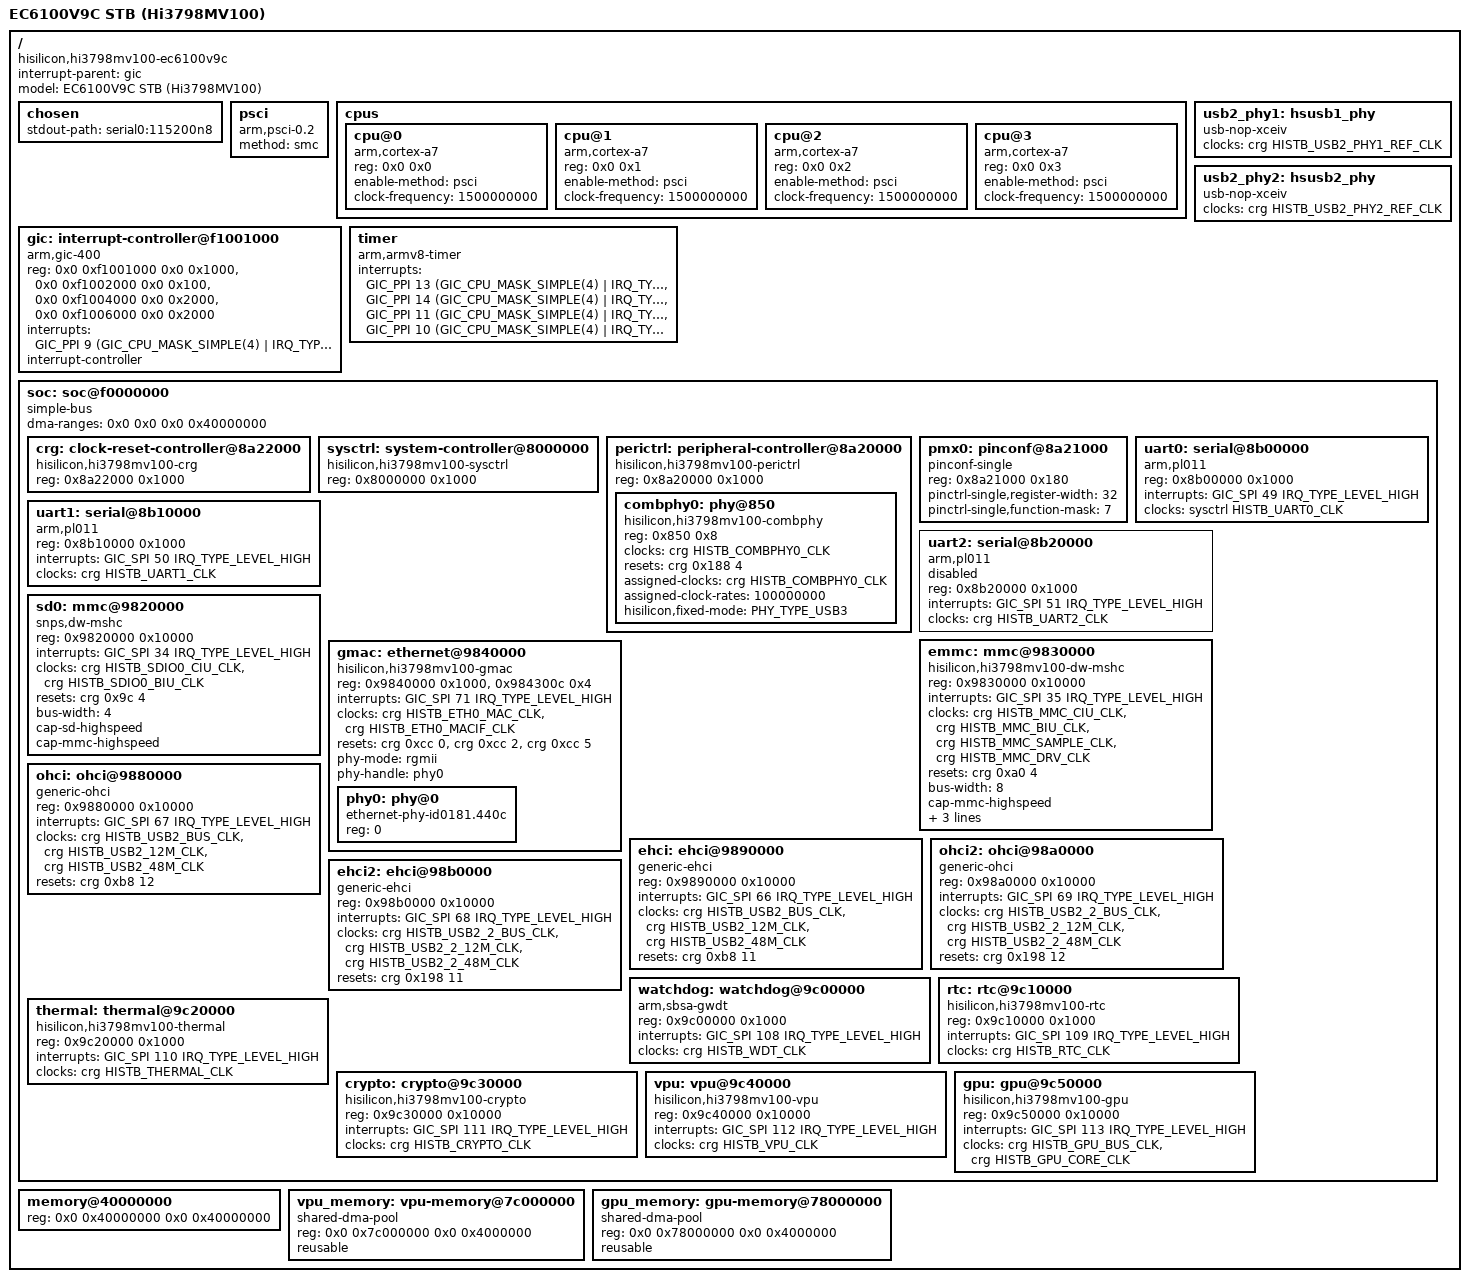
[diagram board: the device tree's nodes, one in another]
/*
 * Device Tree for EC6100V9C STB with Hi3798MV100 SoC
 * Based on Hi3798MV200 device tree and EC6108V9 OpenWrt port
 * Requires Hi3798MV100 kernel patches (David Yang v7, 2023)
 * 
 * SoC: HiSilicon Hi3798MV100
 * CPU: 4x Cortex-A7 @ 1.5GHz
 * RAM: 1GB DDR3
 * Flash: 8GB eMMC
 * Ethernet: 1x 100Mbps (internal GMAC)
 * USB: 2x USB 2.0
 * Video: 4K@30fps H.265/H.264 hardware decoding
 */

// SPDX-License-Identifier: GPL-2.0
/dts-v1/;

#include <dt-bindings/clock/histb-clock.h>
#include <dt-bindings/gpio/gpio.h>
#include <dt-bindings/interrupt-controller/arm-gic.h>
#include <dt-bindings/phy/phy.h>
#include <dt-bindings/reset/ti-syscon.h>

/ {
	compatible = "hisilicon,hi3798mv100-ec6100v9c", "hisilicon,hi3798mv100";
	interrupt-parent = <&gic>;
	#address-cells = <2>;
	#size-cells = <2>;

	model = "EC6100V9C STB (Hi3798MV100)";
	chosen {
		stdout-path = "serial0:115200n8";
	};

	psci {
		compatible = "arm,psci-0.2";
		method = "smc";
	};

	cpus {
		#address-cells = <2>;
		#size-cells = <0>;

		cpu@0 {
			compatible = "arm,cortex-a7";
			device_type = "cpu";
			reg = <0x0 0x0>;
			enable-method = "psci";
			clock-frequency = <1500000000>;
		};

		cpu@1 {
			compatible = "arm,cortex-a7";
			device_type = "cpu";
			reg = <0x0 0x1>;
			enable-method = "psci";
			clock-frequency = <1500000000>;
		};

		cpu@2 {
			compatible = "arm,cortex-a7";
			device_type = "cpu";
			reg = <0x0 0x2>;
			enable-method = "psci";
			clock-frequency = <1500000000>;
		};

		cpu@3 {
			compatible = "arm,cortex-a7";
			device_type = "cpu";
			reg = <0x0 0x3>;
			enable-method = "psci";
			clock-frequency = <1500000000>;
		};
	};

	gic: interrupt-controller@f1001000 {
		compatible = "arm,gic-400";
		reg = <0x0 0xf1001000 0x0 0x1000>,  /* GICD */
		      <0x0 0xf1002000 0x0 0x100>,   /* GICC */
		      <0x0 0xf1004000 0x0 0x2000>,  /* GICH */
		      <0x0 0xf1006000 0x0 0x2000>;  /* GICV */
		interrupts = <GIC_PPI 9 (GIC_CPU_MASK_SIMPLE(4) |
			      IRQ_TYPE_LEVEL_HIGH)>;
		#address-cells = <0>;
		#interrupt-cells = <3>;
		interrupt-controller;
	};

	timer {
		compatible = "arm,armv8-timer";
		interrupts = <GIC_PPI 13 (GIC_CPU_MASK_SIMPLE(4) |
			      IRQ_TYPE_LEVEL_LOW)>,
			     <GIC_PPI 14 (GIC_CPU_MASK_SIMPLE(4) |
			      IRQ_TYPE_LEVEL_LOW)>,
			     <GIC_PPI 11 (GIC_CPU_MASK_SIMPLE(4) |
			      IRQ_TYPE_LEVEL_LOW)>,
			     <GIC_PPI 10 (GIC_CPU_MASK_SIMPLE(4) |
			      IRQ_TYPE_LEVEL_LOW)>;
	};

	/* USB PHYs */
	usb2_phy1: hsusb1_phy {
		compatible = "usb-nop-xceiv";
		clocks = <&crg HISTB_USB2_PHY1_REF_CLK>;
		clock-names = "main";
		#phy-cells = <0>;
	};

	usb2_phy2: hsusb2_phy {
		compatible = "usb-nop-xceiv";
		clocks = <&crg HISTB_USB2_PHY2_REF_CLK>;
		clock-names = "main";
		#phy-cells = <0>;
	};

	soc: soc@f0000000 {
		compatible = "simple-bus";
		#address-cells = <1>;
		#size-cells = <1>;
		ranges = <0x0 0x0 0xf0000000 0x10000000>;
		dma-ranges = <0x0 0x0 0x0 0x40000000>;

		crg: clock-reset-controller@8a22000 {
			compatible = "hisilicon,hi3798mv100-crg", "syscon", "simple-mfd";
			reg = <0x8a22000 0x1000>;
			#clock-cells = <1>;
			#reset-cells = <2>;
		};

		sysctrl: system-controller@8000000 {
			compatible = "hisilicon,hi3798mv100-sysctrl", "syscon";
			reg = <0x8000000 0x1000>;
			#clock-cells = <1>;
			#reset-cells = <2>;
		};

		perictrl: peripheral-controller@8a20000 {
			compatible = "hisilicon,hi3798mv100-perictrl", "syscon",
				     "simple-mfd";
			reg = <0x8a20000 0x1000>;
			#address-cells = <1>;
			#size-cells = <1>;
			ranges = <0x0 0x8a20000 0x1000>;

			combphy0: phy@850 {
				compatible = "hisilicon,hi3798mv100-combphy";
				reg = <0x850 0x8>;
				#phy-cells = <1>;
				clocks = <&crg HISTB_COMBPHY0_CLK>;
				resets = <&crg 0x188 4>;
				assigned-clocks = <&crg HISTB_COMBPHY0_CLK>;
				assigned-clock-rates = <100000000>;
				hisilicon,fixed-mode = <PHY_TYPE_USB3>;
			};
		};

		pmx0: pinconf@8a21000 {
			compatible = "pinconf-single";
			reg = <0x8a21000 0x180>;
			pinctrl-single,register-width = <32>;
			pinctrl-single,function-mask = <7>;
		};

		/* UART0 - Console */
		uart0: serial@8b00000 {
			compatible = "arm,pl011", "arm,primecell";
			reg = <0x8b00000 0x1000>;
			interrupts = <GIC_SPI 49 IRQ_TYPE_LEVEL_HIGH>;
			clocks = <&sysctrl HISTB_UART0_CLK>;
			clock-names = "apb_pclk";
			status = "okay";
		};

		/* UART1 - Often used for Bluetooth or debug */
		uart1: serial@8b10000 {
			compatible = "arm,pl011", "arm,primecell";
			reg = <0x8b10000 0x1000>;
			interrupts = <GIC_SPI 50 IRQ_TYPE_LEVEL_HIGH>;
			clocks = <&crg HISTB_UART1_CLK>;
			clock-names = "apb_pclk";
			status = "okay";
		};

		/* UART2 */
		uart2: serial@8b20000 {
			compatible = "arm,pl011", "arm,primecell";
			reg = <0x8b20000 0x1000>;
			interrupts = <GIC_SPI 51 IRQ_TYPE_LEVEL_HIGH>;
			clocks = <&crg HISTB_UART2_CLK>;
			clock-names = "apb_pclk";
			status = "disabled";
		};

		/* SD/SDIO0 - Usually for SD card */
		sd0: mmc@9820000 {
			compatible = "snps,dw-mshc";
			reg = <0x9820000 0x10000>;
			interrupts = <GIC_SPI 34 IRQ_TYPE_LEVEL_HIGH>;
			clocks = <&crg HISTB_SDIO0_CIU_CLK>,
				 <&crg HISTB_SDIO0_BIU_CLK>;
			clock-names = "ciu", "biu";
			resets = <&crg 0x9c 4>;
			reset-names = "reset";
			bus-width = <4>;
			cap-sd-highspeed;
			cap-mmc-highspeed;
			status = "okay";
		};

		/* eMMC - 8GB internal storage */
		emmc: mmc@9830000 {
			compatible = "hisilicon,hi3798mv100-dw-mshc";
			reg = <0x9830000 0x10000>;
			interrupts = <GIC_SPI 35 IRQ_TYPE_LEVEL_HIGH>;
			clocks = <&crg HISTB_MMC_CIU_CLK>,
				 <&crg HISTB_MMC_BIU_CLK>,
				 <&crg HISTB_MMC_SAMPLE_CLK>,
				 <&crg HISTB_MMC_DRV_CLK>;
			clock-names = "ciu", "biu", "ciu-sample", "ciu-drive";
			resets = <&crg 0xa0 4>;
			reset-names = "reset";
			bus-width = <8>;
			cap-mmc-highspeed;
			cap-mmc-hs200;
			cap-mmc-hs400;
			non-removable;
			status = "okay";
		};

		/* GMAC - 100Mbps Ethernet */
		gmac: ethernet@9840000 {
			compatible = "hisilicon,hi3798mv100-gmac", "hisilicon,hisi-gmac-v2";
			reg = <0x9840000 0x1000>,
			      <0x984300c 0x4>;
			interrupts = <GIC_SPI 71 IRQ_TYPE_LEVEL_HIGH>;
			clocks = <&crg HISTB_ETH0_MAC_CLK>,
				 <&crg HISTB_ETH0_MACIF_CLK>;
			clock-names = "mac_core", "mac_ifc";
			resets = <&crg 0xcc 0>,
				 <&crg 0xcc 2>,
				 <&crg 0xcc 5>;
			reset-names = "mac_core", "mac_ifc", "phy";
			phy-mode = "rgmii";
			phy-handle = <&phy0>;
			status = "okay";

			phy0: phy@0 {
				compatible = "ethernet-phy-id0181.440c";
				reg = <0>;
			};
		};

		/* USB OHCI */
		ohci: ohci@9880000 {
			compatible = "generic-ohci";
			reg = <0x9880000 0x10000>;
			interrupts = <GIC_SPI 67 IRQ_TYPE_LEVEL_HIGH>;
			clocks = <&crg HISTB_USB2_BUS_CLK>,
				 <&crg HISTB_USB2_12M_CLK>,
				 <&crg HISTB_USB2_48M_CLK>;
			clock-names = "bus", "clk12", "clk48";
			resets = <&crg 0xb8 12>;
			reset-names = "bus";
			status = "okay";
		};

		/* USB EHCI */
		ehci: ehci@9890000 {
			compatible = "generic-ehci";
			reg = <0x9890000 0x10000>;
			interrupts = <GIC_SPI 66 IRQ_TYPE_LEVEL_HIGH>;
			clocks = <&crg HISTB_USB2_BUS_CLK>,
				 <&crg HISTB_USB2_12M_CLK>,
				 <&crg HISTB_USB2_48M_CLK>;
			clock-names = "bus", "clk12", "clk48";
			resets = <&crg 0xb8 11>;
			reset-names = "bus";
			status = "okay";
		};

		/* USB2 Second Controller (Hi3798MV100 specific) */
		ohci2: ohci@98a0000 {
			compatible = "generic-ohci";
			reg = <0x98a0000 0x10000>;
			interrupts = <GIC_SPI 69 IRQ_TYPE_LEVEL_HIGH>;
			clocks = <&crg HISTB_USB2_2_BUS_CLK>,
				 <&crg HISTB_USB2_2_12M_CLK>,
				 <&crg HISTB_USB2_2_48M_CLK>;
			clock-names = "bus", "clk12", "clk48";
			resets = <&crg 0x198 12>;
			reset-names = "bus";
			status = "okay";
		};

		ehci2: ehci@98b0000 {
			compatible = "generic-ehci";
			reg = <0x98b0000 0x10000>;
			interrupts = <GIC_SPI 68 IRQ_TYPE_LEVEL_HIGH>;
			clocks = <&crg HISTB_USB2_2_BUS_CLK>,
				 <&crg HISTB_USB2_2_12M_CLK>,
				 <&crg HISTB_USB2_2_48M_CLK>;
			clock-names = "bus", "clk12", "clk48";
			resets = <&crg 0x198 11>;
			reset-names = "bus";
			status = "okay";
		};

		/* Watchdog */
		watchdog: watchdog@9c00000 {
			compatible = "arm,sbsa-gwdt";
			reg = <0x9c00000 0x1000>;
			interrupts = <GIC_SPI 108 IRQ_TYPE_LEVEL_HIGH>;
			clocks = <&crg HISTB_WDT_CLK>;
			status = "okay";
		};

		/* RTC */
		rtc: rtc@9c10000 {
			compatible = "hisilicon,hi3798mv100-rtc";
			reg = <0x9c10000 0x1000>;
			interrupts = <GIC_SPI 109 IRQ_TYPE_LEVEL_HIGH>;
			clocks = <&crg HISTB_RTC_CLK>;
			status = "okay";
		};

		/* Thermal sensor */
		thermal: thermal@9c20000 {
			compatible = "hisilicon,hi3798mv100-thermal";
			reg = <0x9c20000 0x1000>;
			interrupts = <GIC_SPI 110 IRQ_TYPE_LEVEL_HIGH>;
			clocks = <&crg HISTB_THERMAL_CLK>;
			#thermal-sensor-cells = <1>;
			status = "okay";
		};

		/* Crypto engine */
		crypto: crypto@9c30000 {
			compatible = "hisilicon,hi3798mv100-crypto";
			reg = <0x9c30000 0x10000>;
			interrupts = <GIC_SPI 111 IRQ_TYPE_LEVEL_HIGH>;
			clocks = <&crg HISTB_CRYPTO_CLK>;
			status = "okay";
		};

		/* VPU - Video Processing Unit for 4K H.265 */
		vpu: vpu@9c40000 {
			compatible = "hisilicon,hi3798mv100-vpu";
			reg = <0x9c40000 0x10000>;
			interrupts = <GIC_SPI 112 IRQ_TYPE_LEVEL_HIGH>;
			clocks = <&crg HISTB_VPU_CLK>;
			status = "okay";
		};

		/* GPU */
		gpu: gpu@9c50000 {
			compatible = "hisilicon,hi3798mv100-gpu";
			reg = <0x9c50000 0x10000>;
			interrupts = <GIC_SPI 113 IRQ_TYPE_LEVEL_HIGH>;
			clocks = <&crg HISTB_GPU_BUS_CLK>,
				 <&crg HISTB_GPU_CORE_CLK>;
			clock-names = "bus", "core";
			status = "okay";
		};
	};

	/* Memory - 1GB DDR3 */
	memory@40000000 {
		device_type = "memory";
		reg = <0x0 0x40000000 0x0 0x40000000>; /* 1GB at 0x40000000 */
	};

	/* Reserved memory for VPU */
	vpu_memory: vpu-memory@7c000000 {
		compatible = "shared-dma-pool";
		reg = <0x0 0x7c000000 0x0 0x4000000>; /* 64MB at 0x7c000000 */
		reusable;
		status = "okay";
	};

	/* Reserved memory for GPU */
	gpu_memory: gpu-memory@78000000 {
		compatible = "shared-dma-pool";
		reg = <0x0 0x78000000 0x0 0x4000000>; /* 64MB at 0x78000000 */
		reusable;
		status = "okay";
	};
};
